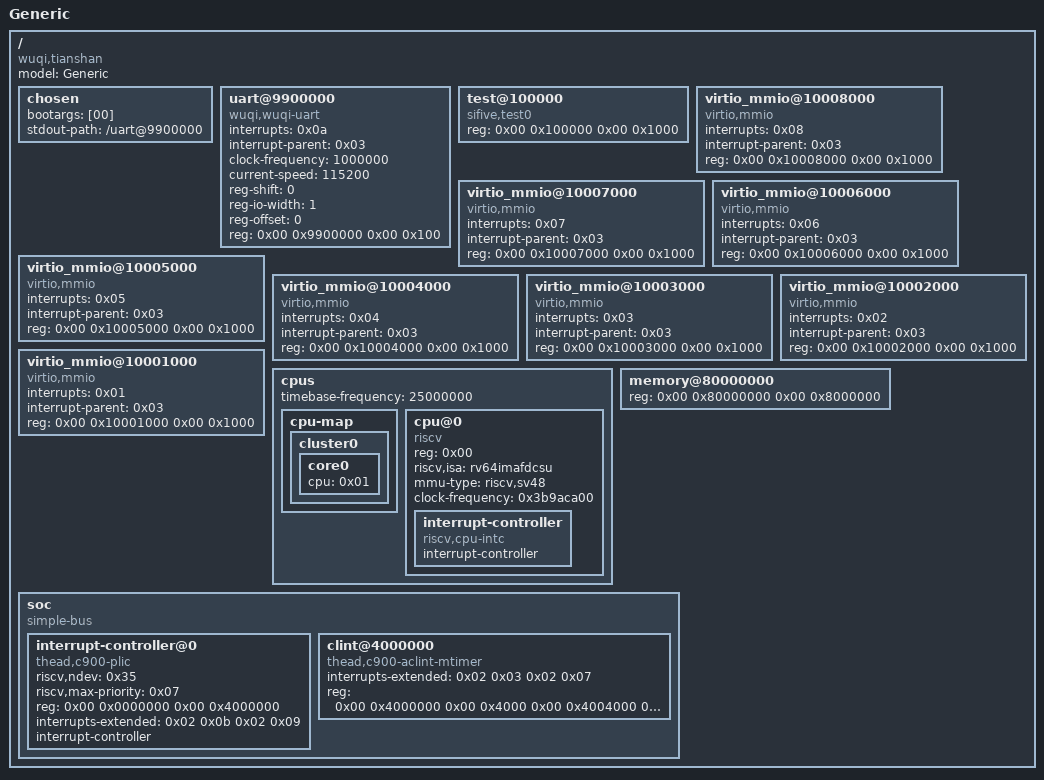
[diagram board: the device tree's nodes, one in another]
/dts-v1/;

/ {
	#address-cells = <0x02>;
	#size-cells = <0x02>;
	compatible = "wuqi,tianshan";
	model = "Generic";

	chosen {
		bootargs = [00];
		stdout-path = "/uart@9900000";
	};

	uart@9900000 {
		interrupts = <0x0a>;
		interrupt-parent = <0x03>;
		clock-frequency = <1000000>;
		current-speed = <115200>;
		reg-shift = <0>;
		reg-io-width = <1>;
		reg-offset = <0>;
		reg = <0x00 0x9900000 0x00 0x100>;
		compatible = "wuqi,wuqi-uart";
	};

	test@100000 {
		reg = <0x00 0x100000 0x00 0x1000>;
		compatible = "sifive,test0";
	};

	virtio_mmio@10008000 {
		interrupts = <0x08>;
		interrupt-parent = <0x03>;
		reg = <0x00 0x10008000 0x00 0x1000>;
		compatible = "virtio,mmio";
	};

	virtio_mmio@10007000 {
		interrupts = <0x07>;
		interrupt-parent = <0x03>;
		reg = <0x00 0x10007000 0x00 0x1000>;
		compatible = "virtio,mmio";
	};

	virtio_mmio@10006000 {
		interrupts = <0x06>;
		interrupt-parent = <0x03>;
		reg = <0x00 0x10006000 0x00 0x1000>;
		compatible = "virtio,mmio";
	};

	virtio_mmio@10005000 {
		interrupts = <0x05>;
		interrupt-parent = <0x03>;
		reg = <0x00 0x10005000 0x00 0x1000>;
		compatible = "virtio,mmio";
	};

	virtio_mmio@10004000 {
		interrupts = <0x04>;
		interrupt-parent = <0x03>;
		reg = <0x00 0x10004000 0x00 0x1000>;
		compatible = "virtio,mmio";
	};

	virtio_mmio@10003000 {
		interrupts = <0x03>;
		interrupt-parent = <0x03>;
		reg = <0x00 0x10003000 0x00 0x1000>;
		compatible = "virtio,mmio";
	};

	virtio_mmio@10002000 {
		interrupts = <0x02>;
		interrupt-parent = <0x03>;
		reg = <0x00 0x10002000 0x00 0x1000>;
		compatible = "virtio,mmio";
	};

	virtio_mmio@10001000 {
		interrupts = <0x01>;
		interrupt-parent = <0x03>;
		reg = <0x00 0x10001000 0x00 0x1000>;
		compatible = "virtio,mmio";
	};

	cpus {
		#address-cells = <0x01>;
		#size-cells = <0x00>;
		timebase-frequency = <25000000>;

		cpu-map {

			cluster0 {

				core0 {
					cpu = <0x01>;
				};
			};
		};

		cpu@0 {
			linux,phandle = <0x01>;
			phandle = <0x01>;
			device_type = "cpu";
			reg = <0x00>;
			status = "okay";
			compatible = "riscv";
			riscv,isa = "rv64imafdcsu";
			mmu-type = "riscv,sv48";
			clock-frequency = <0x3b9aca00>;

			interrupt-controller {
				#interrupt-cells = <0x01>;
				#address-cells = <0x01>;
				interrupt-controller;
				compatible = "riscv,cpu-intc";
				linux,phandle = <0x02>;
				phandle = <0x02>;
			};
		};
	};

	memory@80000000 {
		device_type = "memory";
		reg = <0x00 0x80000000 0x00 0x8000000>;
	};

	soc {
		#address-cells = <0x02>;
		#size-cells = <0x02>;
		compatible = "simple-bus";
		ranges;

		interrupt-controller@0 {
			linux,phandle = <0x03>;
			phandle = <0x03>;
			riscv,ndev = <0x35>;
			riscv,max-priority = <0x07>;
			reg = <0x00 0x0000000 0x00 0x4000000>;
			interrupts-extended = <0x02 0x0b 0x02 0x09>;
			interrupt-controller;
			compatible = "thead,c900-plic";
			status = "okay";
			#interrupt-cells = <0x01>;
			#address-cells = <0x02>;
		};

		clint@4000000 {
			interrupts-extended = <0x02 0x03 0x02 0x07>;
			reg = <0x00 0x4000000 0x00 0x4000 0x00 0x4004000 0x00 0x7FF8 0x00 0x400BFF8 0x00 0x08 0x00 0x400C000 0x00 0x1000 0x00 0x400D000 0x00 0x2FF8 0x00 0x400FFF8 0x00 0x08>;
			reg-names = "msip","mtimecmp","mtime","ssip","stimecmp","stime";
			status = "okay";
			compatible = "thead,c900-aclint-mtimer";
		};
	};
};
